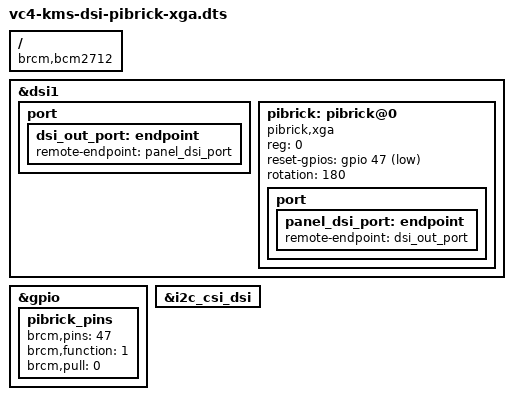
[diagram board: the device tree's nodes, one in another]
/dts-v1/;
/plugin/;
/ {
	compatible = "brcm,bcm2712", "raspberrypi,5-compute-module", "raspberrypi,5-model-b";

	fragment@0 {
		target = <&dsi1>;
		__overlay__{
			status = "okay";
			#address-cells = <1>;
			#size-cells = <0>;
			port {
				dsi_out_port:endpoint {
					remote-endpoint = <&panel_dsi_port>;
				};
			};

			pibrick:pibrick@0 {
				compatible    = "pibrick,xga";
				status        = "okay";
				reg           = <0>;
				reset-gpios   = <&gpio 47 1>;   // Dummy GPIO , Unused
				rotation      = <180>;
				port {
					panel_dsi_port: endpoint {
						remote-endpoint = <&dsi_out_port>;
					};
				};
			};
		};
	};

	fragment@1 {
		target = <&gpio>;
		__overlay__ {
			pibrick_pins: pibrick_pins {
				brcm,pins = <47>;
				brcm,function = <1>; // out
				brcm,pull = <0>; // off
			};
		};

	};
	fragment@2 {
		target = <&i2c_csi_dsi>;
		__overlay__ {
			#address-cells = <1>;
			#size-cells = <0>;
			status = "okay";
		};
	};
};
